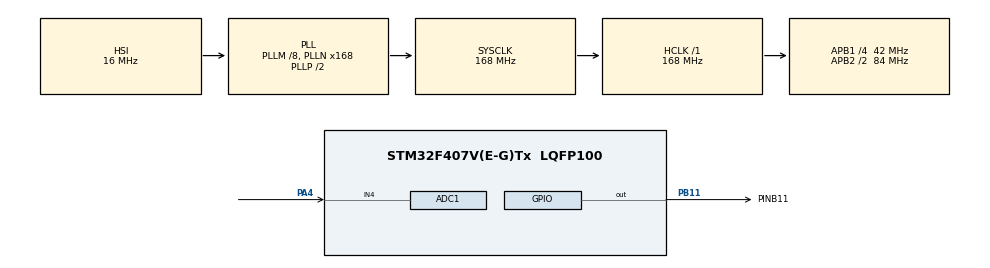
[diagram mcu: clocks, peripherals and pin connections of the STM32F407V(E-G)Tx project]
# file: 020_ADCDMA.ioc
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ADC1.Channel-0\#ChannelRegularConversion=ADC_CHANNEL_4
ADC1.ClockPrescaler=ADC_CLOCK_SYNC_PCLK_DIV8
ADC1.ContinuousConvMode=ENABLE
ADC1.DMAContinuousRequests=ENABLE
ADC1.EOCSelection=ADC_EOC_SEQ_CONV
ADC1.NbrOfConversionFlag=1
ADC1.Rank-0\#ChannelRegularConversion=1
ADC1.SamplingTime-0\#ChannelRegularConversion=ADC_SAMPLETIME_480CYCLES
ADC1.master=1
Dma.ADC1.0.Direction=DMA_PERIPH_TO_MEMORY
Dma.ADC1.0.FIFOMode=DMA_FIFOMODE_DISABLE
Dma.ADC1.0.Instance=DMA2_Stream0
Dma.ADC1.0.MemDataAlignment=DMA_MDATAALIGN_HALFWORD
Dma.ADC1.0.MemInc=DMA_MINC_ENABLE
Dma.ADC1.0.Mode=DMA_CIRCULAR
Dma.ADC1.0.PeriphDataAlignment=DMA_PDATAALIGN_HALFWORD
Dma.ADC1.0.PeriphInc=DMA_PINC_DISABLE
Dma.ADC1.0.Priority=DMA_PRIORITY_LOW
Dma.Request0=ADC1
Mcu.Family=STM32F4
Mcu.Name=STM32F407V(E-G)Tx
Mcu.Package=LQFP100
NVIC.ADC_IRQn=true\:0\:0\:false\:false\:true\:true\:true\:true
NVIC.DMA2_Stream0_IRQn=true\:0\:0\:false\:false\:true\:false\:true\:true
NVIC.PriorityGroup=NVIC_PRIORITYGROUP_4
PA4.Signal=ADCx_IN4
PB11.GPIO_Label=PINB11
PB11.Signal=GPIO_Output
ProjectManager.HeapSize=0x200
ProjectManager.StackSize=0x400
ProjectManager.TargetToolchain=CMake
RCC.48MHZClocksFreq_Value=84000000
RCC.AHBFreq_Value=168000000
RCC.APB1CLKDivider=RCC_HCLK_DIV4
RCC.APB1Freq_Value=42000000
RCC.APB1TimFreq_Value=84000000
RCC.APB2CLKDivider=RCC_HCLK_DIV2
RCC.APB2Freq_Value=84000000
RCC.APB2TimFreq_Value=168000000
RCC.CortexFreq_Value=168000000
RCC.HCLKFreq_Value=168000000
RCC.HSE_VALUE=25000000
RCC.HSI_VALUE=16000000
RCC.LSE_VALUE=32768
RCC.PLLM=8
RCC.PLLN=168
RCC.SYSCLKFreq_VALUE=168000000
RCC.SYSCLKSource=RCC_SYSCLKSOURCE_PLLCLK
RCC.VCOOutputFreq_Value=336000000
SH.ADCx_IN4.0=ADC1_IN4,IN4
board=custom

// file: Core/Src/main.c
/* USER CODE BEGIN Header */
/**
  ******************************************************************************
  * @file           : main.c
  * @brief          : Main program body
  ******************************************************************************
  * @attention
  *
  * Copyright (c) 2026 STMicroelectronics.
  * All rights reserved.
  *
  * This software is licensed under terms that can be found in the LICENSE file
  * in the root directory of this software component.
  * If no LICENSE file comes with this software, it is provided AS-IS.
  *
  ******************************************************************************
  */
/* USER CODE END Header */
#include "main.h"
#include "adc.h"
#include "dma.h"
#include "gpio.h"

/* USER CODE BEGIN Includes */
#include <stdio.h>
#include <nokia1661_lcd_driver.h>

/* USER CODE END Includes */

/* USER CODE BEGIN PD */
#define ADC_MAX_SAMPLES           1000

/* USER CODE END PD */

/* USER CODE BEGIN PV */
uint16_t adcValues[ADC_MAX_SAMPLES] = {0};
uint8_t adcFlag = 0;

/* USER CODE END PV */

void SystemClock_Config(void);

int main(void)
{

  /* MCU Configuration--------------------------------------------------------*/

  /* Reset of all peripherals, Initializes the Flash interface and the Systick. */
  HAL_Init();

  /* Configure the system clock */
  SystemClock_Config();

  /* Initialize all configured peripherals */
  MX_GPIO_Init();
  MX_DMA_Init();
  MX_ADC1_Init();
  /* USER CODE BEGIN 2 */
  HAL_GPIO_WritePin(PINB11_GPIO_Port, PINB11_Pin, GPIO_PIN_SET);
  nlcdInit();

  /* USER CODE END 2 */

  /* Infinite loop */
  /* USER CODE BEGIN WHILE */
  HAL_ADC_Start_DMA(&hadc1, (uint32_t*) adcValues, ADC_MAX_SAMPLES);

  while (1)
  {
    if ((ADC_MAX_SAMPLES - __HAL_DMA_GET_COUNTER(hadc1.DMA_Handle)) % 200 == 0) {   //Overlap
    //if (adcFlag) {                                                                // Normal
      adcFlag = 0;

      // AVG
      uint32_t adcAVG = 0;
      for (uint32_t i = 0; i < ADC_MAX_SAMPLES; i++) {
        adcAVG += adcValues[i];
      }
      adcAVG /= ADC_MAX_SAMPLES;

      // Display
      char val0[32]; sprintf(val0, "%-4lu", adcAVG);
      nlcdStringXY(0, 0, LCD_VGA_SILVER, "ADC-avg:");
      nlcdStringXY(9, 0, LCD_VGA_SILVER, val0);
      char val1[32]; sprintf(val1, "%0.3f", adcAVG * 3.3f / 4096.0f);
      nlcdStringXY(0, 1, LCD_VGA_BLUE, "Voltage:");
      nlcdStringXY(9, 1, LCD_VGA_BLUE, val1);
    }
    /* USER CODE END WHILE */

  }
}

void SystemClock_Config(void)
{
  RCC_OscInitTypeDef RCC_OscInitStruct = {0};
  RCC_ClkInitTypeDef RCC_ClkInitStruct = {0};

  /** Configure the main internal regulator output voltage
  */
  __HAL_RCC_PWR_CLK_ENABLE();
  __HAL_PWR_VOLTAGESCALING_CONFIG(PWR_REGULATOR_VOLTAGE_SCALE1);

  /** Initializes the RCC Oscillators according to the specified parameters
  * in the RCC_OscInitTypeDef structure.
  */
  RCC_OscInitStruct.OscillatorType = RCC_OSCILLATORTYPE_HSI;
  RCC_OscInitStruct.HSIState = RCC_HSI_ON;
  RCC_OscInitStruct.HSICalibrationValue = RCC_HSICALIBRATION_DEFAULT;
  RCC_OscInitStruct.PLL.PLLState = RCC_PLL_ON;
  RCC_OscInitStruct.PLL.PLLSource = RCC_PLLSOURCE_HSI;
  RCC_OscInitStruct.PLL.PLLM = 8;
  RCC_OscInitStruct.PLL.PLLN = 168;
  RCC_OscInitStruct.PLL.PLLP = RCC_PLLP_DIV2;
  RCC_OscInitStruct.PLL.PLLQ = 4;
  if (HAL_RCC_OscConfig(&RCC_OscInitStruct) != HAL_OK)
  {
    Error_Handler();
  }

  /** Initializes the CPU, AHB and APB buses clocks
  */
  RCC_ClkInitStruct.ClockType = RCC_CLOCKTYPE_HCLK|RCC_CLOCKTYPE_SYSCLK
                              |RCC_CLOCKTYPE_PCLK1|RCC_CLOCKTYPE_PCLK2;
  RCC_ClkInitStruct.SYSCLKSource = RCC_SYSCLKSOURCE_PLLCLK;
  RCC_ClkInitStruct.AHBCLKDivider = RCC_SYSCLK_DIV1;
  RCC_ClkInitStruct.APB1CLKDivider = RCC_HCLK_DIV4;
  RCC_ClkInitStruct.APB2CLKDivider = RCC_HCLK_DIV2;

  if (HAL_RCC_ClockConfig(&RCC_ClkInitStruct, FLASH_LATENCY_5) != HAL_OK)
  {
    Error_Handler();
  }
}

/* USER CODE BEGIN 4 */

void HAL_ADC_ConvCpltCallback(ADC_HandleTypeDef* hadc) {
  adcFlag = 1;
}

/* USER CODE END 4 */

void Error_Handler(void)
{
  __disable_irq();
  while (1)
  {
  }
}
